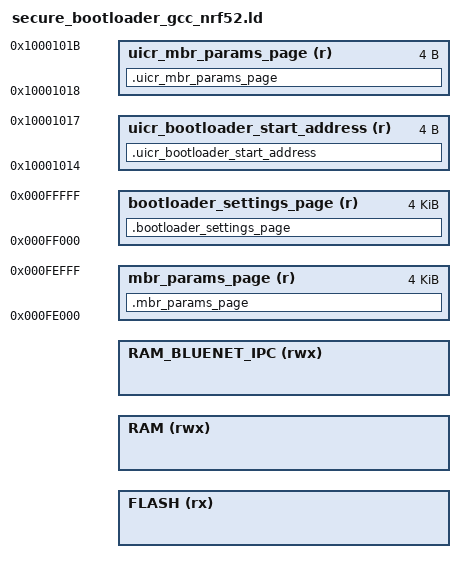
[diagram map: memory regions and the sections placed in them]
/* Linker script to configure memory regions. */

SEARCH_DIR(.)
GROUP(-lgcc -lc -lnosys)

INCLUDE "nrf_symbols.ld"

RAM_START = RAM_R1_BASE + RAM_BOOTLOADER_START_OFFSET;
RAM_LENGTH = (RAM_APPLICATION_AMOUNT - RAM_BOOTLOADER_START_OFFSET) - RAM_BLUENET_IPC_LENGTH;

RAM_BLUENET_IPC_START = (RAM_START + RAM_LENGTH);

MEMORY
{
  /* Without debug: FLASH (rx) : ORIGIN = 0x76000, LENGTH = 0x8000 */
  /* With debug:    FLASH (rx) : ORIGIN = 0x71000, LENGTH = 0xd000 */
  /* FLASH (rx) : ORIGIN = 0x71000, LENGTH = 0xd000 */
  /* Without gc-sections: FLASH (rx) : ORIGIN = 0x68000, LENGTH = 0x10000 */
  FLASH (rx) : ORIGIN = BOOTLOADER_START_ADDRESS, LENGTH = BOOTLOADER_LENGTH
  RAM (rwx) :  ORIGIN = RAM_START, LENGTH = RAM_LENGTH
  RAM_BLUENET_IPC (rwx): ORIGIN = RAM_BLUENET_IPC_START, LENGTH = RAM_BLUENET_IPC_LENGTH
  mbr_params_page (r) : ORIGIN = 0x000FE000, LENGTH = 0x1000
  bootloader_settings_page (r) : ORIGIN = 0x000FF000, LENGTH = 0x1000
  uicr_mbr_params_page (r) : ORIGIN = 0x10001018, LENGTH = 0x4
  uicr_bootloader_start_address (r) : ORIGIN = 0x10001014, LENGTH = 0x4
}

SECTIONS
{
  .mbr_params_page(NOLOAD) :
  {
    PROVIDE(__start_mbr_params_page = .);
    KEEP(*(SORT(.mbr_params_page*)))
    PROVIDE(__stop_mbr_params_page = .);
  } > mbr_params_page
  .bootloader_settings_page(NOLOAD) :
  {
    PROVIDE(__start_bootloader_settings_page = .);
    KEEP(*(SORT(.bootloader_settings_page*)))
    PROVIDE(__stop_bootloader_settings_page = .);
  } > bootloader_settings_page
  .uicr_mbr_params_page :
  {
    PROVIDE(__start_uicr_mbr_params_page = .);
    KEEP(*(SORT(.uicr_mbr_params_page*)))
    PROVIDE(__stop_uicr_mbr_params_page = .);
  } > uicr_mbr_params_page
  .uicr_bootloader_start_address :
  {
    PROVIDE(__start_uicr_bootloader_start_address = .);
    KEEP(*(SORT(.uicr_bootloader_start_address*)))
    PROVIDE(__stop_uicr_bootloader_start_address = .);
  } > uicr_bootloader_start_address
}

SECTIONS
{
  . = ALIGN(4);
  .bluenet_ipc_ram (NOLOAD):
  {
    PROVIDE(__start_bluenet_ipc_ram = .);
    KEEP(*(SORT(.bluenet_ipc_ram.*)))
    PROVIDE(__stop_bluenet_ipc_ram = .);
  } > RAM_BLUENET_IPC
}

SECTIONS
{
  . = ALIGN(4);
  .mem_section_dummy_ram :
  {
  }
  .log_dynamic_data :
  {
    PROVIDE(__start_log_dynamic_data = .);
    KEEP(*(SORT(.log_dynamic_data*)))
    PROVIDE(__stop_log_dynamic_data = .);
  } > RAM
  .log_filter_data :
  {
    PROVIDE(__start_log_filter_data = .);
    KEEP(*(SORT(.log_filter_data*)))
    PROVIDE(__stop_log_filter_data = .);
  } > RAM
  .fs_data :
  {
    PROVIDE(__start_fs_data = .);
    KEEP(*(.fs_data))
    PROVIDE(__stop_fs_data = .);
  } > RAM

} INSERT AFTER .data;

SECTIONS
{
  .mem_section_dummy_rom :
  {
  }
  .crypto_data :
  {
    PROVIDE(__start_crypto_data = .);
    KEEP(*(SORT(.crypto_data*)))
    PROVIDE(__stop_crypto_data = .);
  } > FLASH
    .nrf_queue :
  {
    PROVIDE(__start_nrf_queue = .);
    KEEP(*(.nrf_queue))
    PROVIDE(__stop_nrf_queue = .);
  } > FLASH
  .dfu_trans :
  {
    PROVIDE(__start_dfu_trans = .);
    KEEP(*(SORT(.dfu_trans*)))
    PROVIDE(__stop_dfu_trans = .);
  } > FLASH
    .svc_data :
  {
    PROVIDE(__start_svc_data = .);
    KEEP(*(.svc_data))
    PROVIDE(__stop_svc_data = .);
  } > FLASH
  .log_const_data :
  {
    PROVIDE(__start_log_const_data = .);
    KEEP(*(SORT(.log_const_data*)))
    PROVIDE(__stop_log_const_data = .);
  } > FLASH
    .nrf_balloc :
  {
    PROVIDE(__start_nrf_balloc = .);
    KEEP(*(.nrf_balloc))
    PROVIDE(__stop_nrf_balloc = .);
  } > FLASH
  .sdh_ble_observers :
  {
    PROVIDE(__start_sdh_ble_observers = .);
    KEEP(*(SORT(.sdh_ble_observers*)))
    PROVIDE(__stop_sdh_ble_observers = .);
  } > FLASH
  .log_backends :
  {
    PROVIDE(__start_log_backends = .);
    KEEP(*(SORT(.log_backends*)))
    PROVIDE(__stop_log_backends = .);
  } > FLASH
  .sdh_stack_observers :
  {
    PROVIDE(__start_sdh_stack_observers = .);
    KEEP(*(SORT(.sdh_stack_observers*)))
    PROVIDE(__stop_sdh_stack_observers = .);
  } > FLASH
  .sdh_req_observers :
  {
    PROVIDE(__start_sdh_req_observers = .);
    KEEP(*(SORT(.sdh_req_observers*)))
    PROVIDE(__stop_sdh_req_observers = .);
  } > FLASH
  .sdh_state_observers :
  {
    PROVIDE(__start_sdh_state_observers = .);
    KEEP(*(SORT(.sdh_state_observers*)))
    PROVIDE(__stop_sdh_state_observers = .);
  } > FLASH
  .sdh_soc_observers :
  {
    PROVIDE(__start_sdh_soc_observers = .);
    KEEP(*(SORT(.sdh_soc_observers*)))
    PROVIDE(__stop_sdh_soc_observers = .);
  } > FLASH

} INSERT AFTER .text

INCLUDE "nrf_common.ld"
